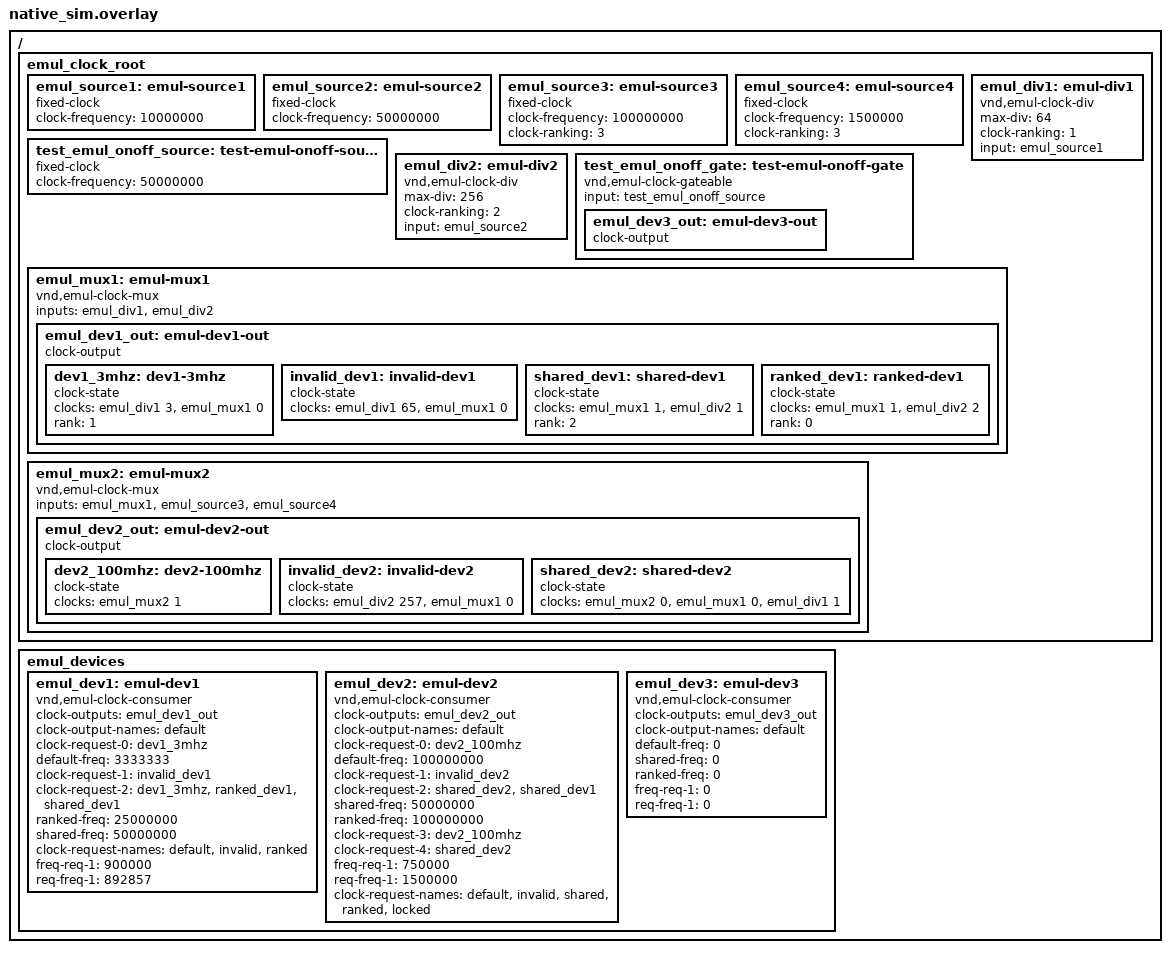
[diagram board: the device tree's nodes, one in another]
/*
 * Copyright 2024 NXP
 * Copyright (c) 2025, Tenstorrent AI ULC
 * Copyright (c) 2026 Analog Devices, Inc
 *
 * SPDX-License-Identifier: Apache-2.0
 */

/*
 * Define clock tree with emulated clock nodes.
 * These node labels are chosen so that they won't conflict with SOC clock
 * tree nodelabels. The clock driver implementations used by this tree are
 * stored within the test itself
 */

/ {
	emul_clock_root {
		emul_source1: emul-source1 {
			compatible = "fixed-clock";
			clock-frequency = <10000000>;
			#clock-cells = <0>;
		};

		emul_source2: emul-source2 {
			compatible = "fixed-clock";
			clock-frequency = <50000000>;
			#clock-cells = <0>;
		};

		emul_source3: emul-source3 {
			compatible = "fixed-clock";
			clock-frequency = <100000000>;
			#clock-cells = <0>;
			clock-ranking = <3>;
		};

		emul_source4: emul-source4 {
			compatible = "fixed-clock";
			clock-frequency = <1500000>;
			#clock-cells = <0>;
			clock-ranking = <3>;
		};

		test_emul_onoff_source: test-emul-onoff-source {
			compatible = "fixed-clock";
			clock-frequency = <50000000>;
			#clock-cells = <0>;
		};

		emul_div1: emul-div1 {
			compatible = "vnd,emul-clock-div";
			max-div = <64>;
			#clock-cells = <1>;
			clock-ranking = <1>;
			input = <&emul_source1>;
		};

		emul_div2: emul-div2 {
			compatible = "vnd,emul-clock-div";
			max-div = <256>;
			#clock-cells = <1>;
			clock-ranking = <2>;
			input = <&emul_source2>;
		};

		test_emul_onoff_gate: test-emul-onoff-gate {
			compatible = "vnd,emul-clock-gateable";
			#clock-cells = <0>;
			input = <&test_emul_onoff_source>;

			emul_dev3_out: emul-dev3-out {
				compatible = "clock-output";
				#clock-cells = <0>;
			};
		};

		emul_mux1: emul-mux1 {
			compatible = "vnd,emul-clock-mux";
			inputs = <&emul_div1 &emul_div2>;
			#clock-cells = <1>;

			emul_dev1_out: emul-dev1-out {
				compatible = "clock-output";
				#clock-cells = <0>;

				/* Expect a clock frequency of 3.333333 MHz */
				dev1_3mhz: dev1-3mhz {
					compatible = "clock-state";
					clocks = <&emul_div1 3 &emul_mux1 0>;
					rank = <1>;
				};

				/* Expect error when applying this invalid state */
				invalid_dev1: invalid-dev1 {
					compatible = "clock-state";
					clocks = <&emul_div1 65 &emul_mux1 0>;
				};

				/* Frequency for this state should be 50 MHz */
				shared_dev1: shared-dev1 {
					compatible = "clock-state";
					clocks = <&emul_mux1 1 &emul_div2 1>;
					rank = <2>;
				};

				ranked_dev1: ranked-dev1 {
					compatible = "clock-state";
					clocks = <&emul_mux1 1 &emul_div2 2>;
					rank = <0>;
				};
			};
		};

		emul_mux2: emul-mux2 {
			compatible = "vnd,emul-clock-mux";
			inputs = <&emul_mux1 &emul_source3 &emul_source4>;
			#clock-cells = <1>;

			emul_dev2_out: emul-dev2-out {
				compatible = "clock-output";
				#clock-cells = <0>;

				/* Expect a clock frequency of 100 MHz */
				dev2_100mhz: dev2-100mhz {
					compatible = "clock-state";
					clocks = <&emul_mux2 1>;
				};

				/* Expect error when applying this invalid state */
				invalid_dev2: invalid-dev2 {
					compatible = "clock-state";
					clocks = <&emul_div2 257 &emul_mux1 0>;
				};

				/* Expect frequency of 10 MHz. When shared_dev1 is applied
				 * alongside this, the resulting frequency will be 50MHz.
				 */
				shared_dev2: shared-dev2 {
					compatible = "clock-state";
					clocks = <&emul_mux2 0 &emul_mux1 0
						  &emul_div1 1>;
				};
			};
		};
	};

	/* Emulated device clock consumers */
	emul_devices {
		emul_dev1: emul-dev1 {
			compatible = "vnd,emul-clock-consumer";
			clock-outputs = <&emul_dev1_out>;
			clock-output-names = "default";
			clock-request-0 = <&dev1_3mhz>;
			default-freq = <3333333>;
			clock-request-1 = <&invalid_dev1>;
			clock-request-2 = <&dev1_3mhz &ranked_dev1 &shared_dev1>;
			ranked-freq = <25000000>;
			shared-freq = <50000000>;
			clock-request-names = "default", "invalid", "ranked";
			freq-req-1 = <900000>;
			req-freq-1 = <892857>;
		};

		emul_dev2: emul-dev2 {
			compatible = "vnd,emul-clock-consumer";
			clock-outputs = <&emul_dev2_out>;
			clock-output-names = "default";
			clock-request-0 = <&dev2_100mhz>;
			default-freq = <100000000>;
			clock-request-1 = <&invalid_dev2>;
			clock-request-2 = <&shared_dev2 &shared_dev1>;
			shared-freq = <50000000>;
			ranked-freq = <100000000>;
			clock-request-3 = <&dev2_100mhz>;
			/* This state will fail to apply when the first consumer has
			 * locked clocks
			 */
			clock-request-4 = <&shared_dev2>;
			freq-req-1 = <750000>;
			req-freq-1 = <1500000>;
			clock-request-names = "default", "invalid", "shared",
					      "ranked", "locked";
		};

		emul_dev3: emul-dev3 {
			compatible = "vnd,emul-clock-consumer";
			clock-outputs = <&emul_dev3_out>;
			clock-output-names = "default";
			/* Below properties aren't used on this node */
			default-freq = <0>;
			shared-freq = <0>;
			ranked-freq = <0>;
			freq-req-1 = <0>;
			req-freq-1 = <0>;
		};
	};
};
